# STM32G0B1xx register map
File version: 1.0
Registers are 32-bit, read-write, reset 0x0 unless marked. A register's access mark holds for its fields unless they carry their own. Offsets are from the block's base; [hi:lo] are bit positions; {n}, {i} and the like mark numbered series.

## USB_DRD_PMA_BUFF — Universal Serial Bus PacketMemoryArea Buffer Descriptor Table
Base 0x40009800
0x00 TXBD — Transmission buffer address
0x04 RXBD — Reception buffer address

## TAMP — Tamper and backup registers
Base 0x4000B000
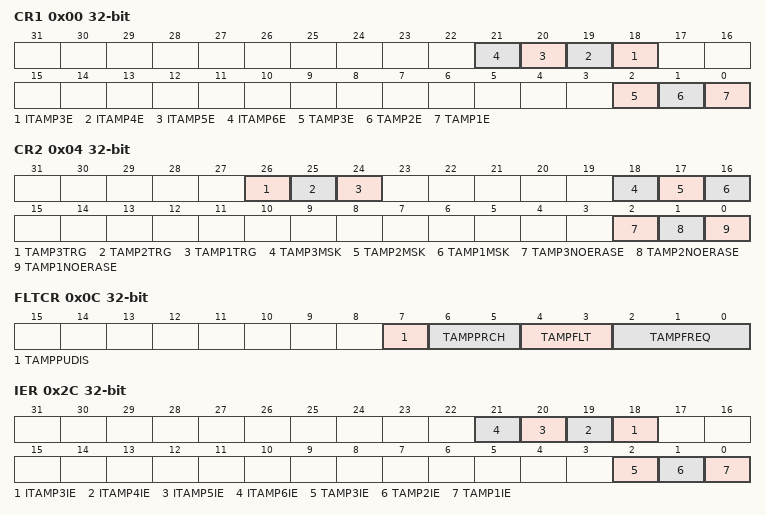
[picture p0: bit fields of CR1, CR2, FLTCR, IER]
0x00 CR1 — TAMP configuration register 1
  [n+15] ITAMP{n}E (n=3..6), [2] TAMP3E, [1] TAMP2E, [0] TAMP1E
0x04 CR2 — TAMP configuration register 2
  [26] TAMP3TRG, [25] TAMP2TRG, [24] TAMP1TRG, [18] TAMP3MSK, [17] TAMP2MSK, [16] TAMP1MSK, [2] TAMP3NOERASE, [1] TAMP2NOERASE, [0] TAMP1NOERASE
0x0C FLTCR — Reserved
  [7] TAMPPUDIS
  [6:5] TAMPPRCH
    0=DURATION_1RTCCLK (Tamper pins are pre-charged before sampling during 1 RTCCLK cycle); 1=DURATION_2RTCCLK (Tamper pins are pre-charged before sampling during 2 RTCCLK cycles); 2=DURATION_4RTCCLK (Tamper pins are pre-charged before sampling during 4 RTCCLK cycles); 3=DURATION_8RTCCLK (Tamper pins are pre-charged before sampling during 8 RTCCLK cycles)
  [4:3] TAMPFLT
    0=DISABLE (Tamper filter is disabled); 1=FILTER_2SAMPLE (Tamper is activated after 2 consecutive samples at the active level); 2=FILTER_4SAMPLE (Tamper is activated after 4 consecutive samples at the active level); 3=FILTER_8SAMPLE (Tamper is activated after 8 consecutive samples at the active level.)
  [2:0] TAMPFREQ
    0=SAMPLFREQDIV_32768 (Each of the tamper inputs are sampled with a frequency = RTCCLK / 32768); 1=SAMPLFREQDIV_16384 (Each of the tamper inputs are sampled with a frequency = RTCCLK / 16384); 2=SAMPLFREQDIV_8192 (Each of the tamper inputs are sampled with a frequency = RTCCLK / 8192); 3=SAMPLFREQDIV_4096 (Each of the tamper inputs are sampled with a frequency = RTCCLK / 4096); 4=SAMPLFREQDIV_2048 (Each of the tamper inputs are sampled with a frequency = RTCCLK / 2048); 5=SAMPLFREQDIV_1024 (Each of the tamper inputs are sampled with a frequency = RTCCLK / 1024); 6=SAMPLFREQDIV_512 (Each of the tamper inputs are sampled with a frequency = RTCCLK / 512); 7=SAMPLFREQDIV_256 (Each of the tamper inputs are sampled with a frequency = RTCCLK / 256)
0x2C IER — TAMP Interrupt enable register
  [n+15] ITAMP{n}IE (n=3..6), [2] TAMP3IE, [1] TAMP2IE, [0] TAMP1IE
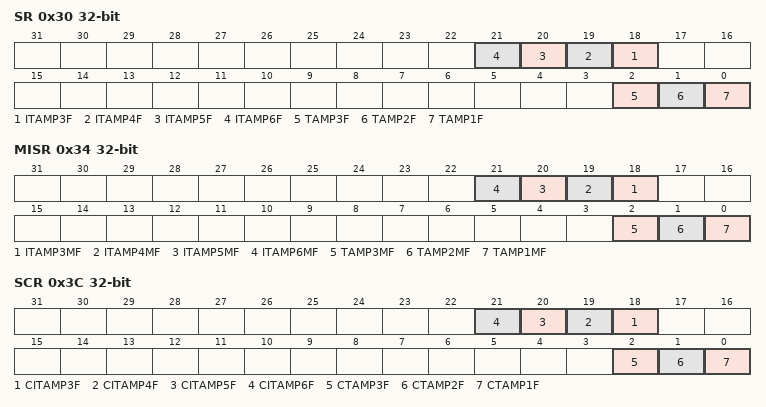
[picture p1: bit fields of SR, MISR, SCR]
0x30 SR — TAMP Status register
  [n+15] ITAMP{n}F (n=3..6), [2] TAMP3F, [1] TAMP2F, [0] TAMP1F
0x34 MISR — TAMP Masked Interrupt Status register
  [n+15] ITAMP{n}MF (n=3..6), [2] TAMP3MF, [1] TAMP2MF, [0] TAMP1MF
0x3C SCR — TAMP Status clear register
  [n+15] CITAMP{n}F (n=3..6), [2] CTAMP3F, [1] CTAMP2F, [0] CTAMP1F
{0x100+4i} BKP{i}R (i=0..4) — TAMP backup register {i}

## VREFBUF
Base 0x40010030
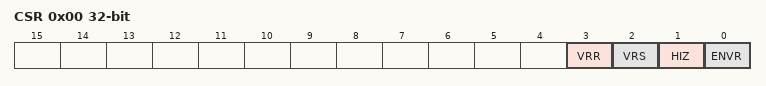
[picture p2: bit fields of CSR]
0x00 CSR — VREFBUF control and status register
  [3] VRR — Voltage reference buffer ready
  [2] VRS — Voltage reference scale
    0=SCALE0 (Voltage reference scale 0 (VREF_OUT1)); 1=SCALE1 (Voltage reference scale 1 (VREF_OUT2))
  [1] HIZ — High impedance mode
  [0] ENVR — Voltage reference buffer enable
0x04 CCR — VREFBUF calibration and control register
  [5:0] TRIM — TRIM[5:0] bits (Trimming code)

## COMP1 — Comparator
Base 0x40010200
Same registers: COMP2 0x40010204, COMP3 0x40010208
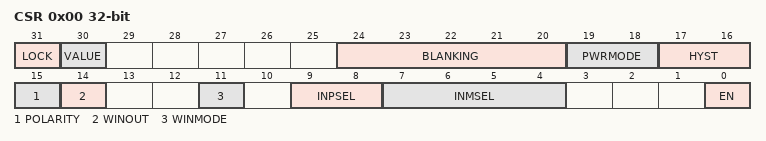
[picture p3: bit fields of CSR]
0x00 CSR — COMP control and status register
  [31] LOCK — Comparator lock
  [30] VALUE — Comparator output level
  [24:20] BLANKING — Comparator blanking source
    0=NONE (Comparator output without blanking); 1=TIM1_OC4 (Comparator output blanking source TIM1 OC4 (common to all COMP instances: COMP1, COMP2, COMP3 (when available))); 2=TIM1_OC5 (Comparator output blanking source TIM1 OC5 (common to all COMP instances: COMP1, COMP2, COMP3 (when available))); 4=TIM2_OC3 (Comparator output blanking source TIM2 OC3 (common to all COMP instances: COMP1, COMP2, COMP3 (when available))); 8=TIM3_OC3 (Comparator output blanking source TIM3 OC3 (common to all COMP instances: COMP1, COMP2, COMP3 (when available))); 16=TIM15_OC2 (Comparator output blanking source TIM15 OC2 (common to all COMP instances: COMP1, COMP2, COMP3 (when available)))
  [19:18] PWRMODE — Comparator power mode
    0=HIGHSPEED (COMP power mode to high speed); 1=MEDIUMSPEED (COMP power mode to medium speed)
  [17:16] HYST — Comparator input hysteresis
    0=NONE (No hysteresis); 1=LOW (Hysteresis level low); 2=MEDIUM (Hysteresis level medium); 3=HIGH (Hysteresis level high)
  [15] POLARITY — Comparator output polarity
    0=NONINVERTED (COMP output polarity is not inverted: comparator output is high when the plus (non-inverting) input is at a higher voltage than the minus (inverting) input); 1=INVERTED (COMP output polarity is inverted: comparator output is low when the plus (non-inverting) input is at a lower voltage than the minus (inverting) input)
  [14] WINOUT — Pair of comparators window output level. Bit intended to be used with COMP common instance (COMP_Common_TypeDef)
  [11] WINMODE — Pair of comparators window mode. Bit intended to be used with COMP common instance (COMP_Common_TypeDef)
  [9:8] INPSEL — Comparator plus minus selection
    0=IO1 (Comparator input plus connected to IO1 (pin PC5 for COMP1, pin PB4 for COMP2, pin PB0 for COMP3 (for devices featuring COMP3 instance))); 1=IO2 (Comparator input plus connected to IO2 (pin PB2 for COMP1, pin PB6 for COMP2, pin PC1 for COMP3 (for devices featuring COMP3 instance))); 2=IO3 (Comparator input plus connected to IO3 (pin PA1 for COMP1, pin PA3 for COMP2, pin PE7 for COMP3 (for devices featuring COMP3 instance)))
  [7:4] INMSEL — Comparator input minus selection
    0=MINUS_1_4VREFINT (Comparator input minus connected to 1/4 VrefInt); 1=MINUS_1_2VREFINT (Comparator input minus connected to 1/2 VrefInt); 2=MINUS_3_4VREFINT (Comparator input minus connected to 3/4 VrefInt); 3=VREFINT (Comparator input minus connected to VrefInt); 4=DAC1_CH1 (Comparator input minus connected to DAC1 channel 1 (DAC_OUT1)); 5=DAC1_CH2 (Comparator input minus connected to DAC1 channel 2 (DAC_OUT2)); 6=IO1 (Comparator input minus connected to IO1 (pin PB1 for COMP1, pin PB3 for COMP2, pin PB2 for COMP3 (for devices featuring COMP3 instance))); 7=IO2 (Comparator input minus connected to IO2 (pin PC4 for COMP1, pin PB7 for COMP2, pin PC0 for COMP3 (for devices featuring COMP3 instance))); 8=IO3 (Comparator input minus connected to IO3 (pin PA0 for COMP1, pin PA2 for COMP2, pin PE8 for COMP3 (for devices featuring COMP3 instance)))
  [0] EN — Comparator enable
